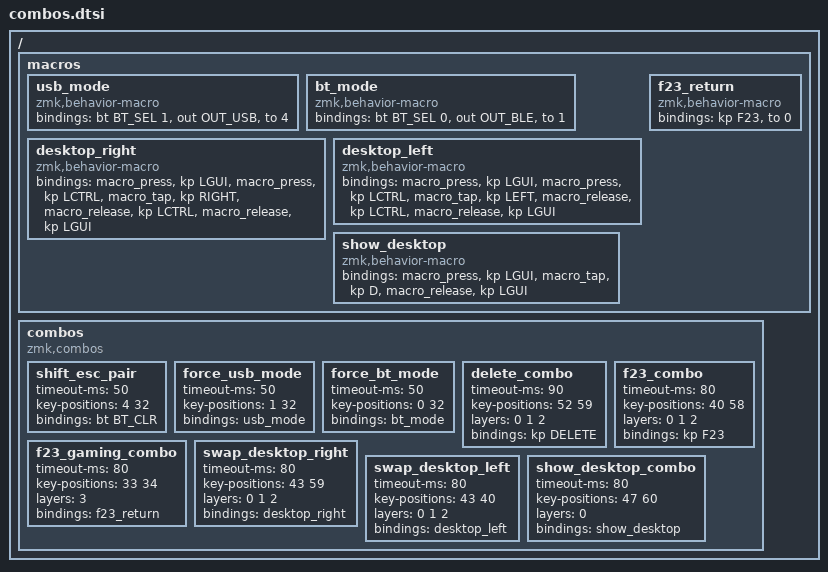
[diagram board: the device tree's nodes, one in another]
#include <dt-bindings/zmk/bt.h>
#include <dt-bindings/zmk/outputs.h>

/ {
    macros {

        usb_mode: usb_mode {
            compatible = "zmk,behavior-macro";
            #binding-cells = <0>;
            bindings = <&bt BT_SEL 1>, <&out OUT_USB>, <&to 4>;
        };

        bt_mode: bt_mode {
            compatible = "zmk,behavior-macro";
            #binding-cells = <0>;
            bindings = <&bt BT_SEL 0>, <&out OUT_BLE>, <&to 1>;
        };

        desktop_right: desktop_right {
            compatible = "zmk,behavior-macro";
            #binding-cells = <0>;
            bindings
                = <&macro_press &kp LGUI>
                , <&macro_press &kp LCTRL>
                , <&macro_tap &kp RIGHT>
                , <&macro_release &kp LCTRL>
                , <&macro_release &kp LGUI>;
        };

        desktop_left: desktop_left {
            compatible = "zmk,behavior-macro";
            #binding-cells = <0>;
            bindings
                = <&macro_press &kp LGUI>
                , <&macro_press &kp LCTRL>
                , <&macro_tap &kp LEFT>
                , <&macro_release &kp LCTRL>
                , <&macro_release &kp LGUI>;


        };

	f23_return: f23_return {
	    compatible = "zmk,behavior-macro";
	    #binding-cells = <0>;
	    bindings = <&kp F23>, <&to 0>;
	};

	show_desktop: show_desktop {
	    compatible = "zmk,behavior-macro";
	    #binding-cells = <0>;
	    bindings
	        = <&macro_press &kp LGUI>
	        , <&macro_tap &kp D>
	        , <&macro_release &kp LGUI>;
	};
    };

    combos {
        compatible = "zmk,combos";

        shift_esc_pair {
            timeout-ms = <50>;
            key-positions = <4 32>;
            bindings = <&bt BT_CLR>;
        };

        force_usb_mode {
            timeout-ms = <50>;
            key-positions = <1 32>;
            bindings = <&usb_mode>;
        };

        force_bt_mode {
            timeout-ms = <50>;
            key-positions = <0 32>;
            bindings = <&bt_mode>;
        };

        delete_combo {
            timeout-ms = <90>;
            key-positions = <52 59>;
            layers = <0 1 2>;
            bindings = <&kp DELETE>;
        };

	f23_combo {
	    timeout-ms = <80>;
	    key-positions = <40 58>;
	    layers = <0 1 2>;
	    bindings = <&kp F23>;
	};

	f23_gaming_combo {
    	timeout-ms = <80>;
	    key-positions = <33 34>;
	    layers = <3>;
	    bindings = <&f23_return>;
	};

        swap_desktop_right {
            timeout-ms = <80>;
            key-positions = <43 59>;
            layers = <0 1 2>;
            bindings = <&desktop_right>;
        };

        swap_desktop_left {
            timeout-ms = <80>;
            key-positions = <43 40>;
            layers = <0 1 2>;
            bindings = <&desktop_left>;
        };

	show_desktop_combo {
	    timeout-ms = <80>;
	    key-positions = <47 60>;
	    layers = <0>;
	    bindings = <&show_desktop>;
	};	
    };
};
